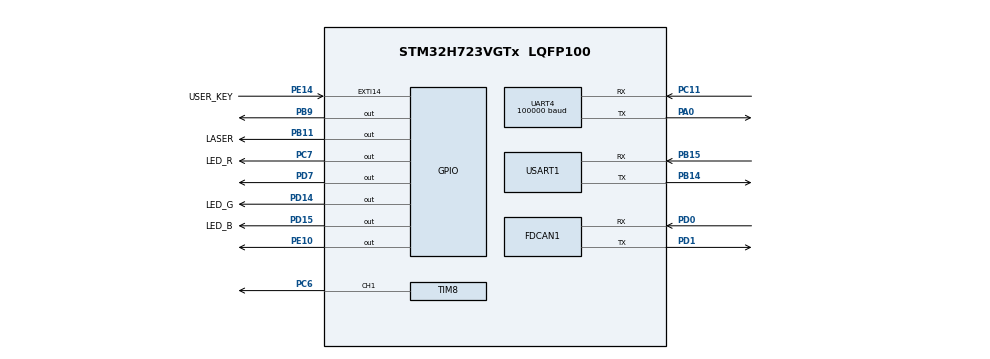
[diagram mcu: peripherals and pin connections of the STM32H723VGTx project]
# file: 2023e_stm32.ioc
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CORTEX_M7.CPU_DCache=Disabled
CORTEX_M7.CPU_ICache=Disabled
CORTEX_M7.MPU_Control=__NULL
CORTEX_M7.default_mode_Activation=0
Dma.Request0=USART1_RX
Dma.Request1=USART1_TX
Dma.Request2=UART4_RX
Dma.UART4_RX.2.Direction=DMA_PERIPH_TO_MEMORY
Dma.UART4_RX.2.EventEnable=DISABLE
Dma.UART4_RX.2.FIFOMode=DMA_FIFOMODE_DISABLE
Dma.UART4_RX.2.Instance=DMA1_Stream2
Dma.UART4_RX.2.MemDataAlignment=DMA_MDATAALIGN_BYTE
Dma.UART4_RX.2.MemInc=DMA_MINC_ENABLE
Dma.UART4_RX.2.Mode=DMA_NORMAL
Dma.UART4_RX.2.PeriphDataAlignment=DMA_PDATAALIGN_BYTE
Dma.UART4_RX.2.PeriphInc=DMA_PINC_DISABLE
Dma.UART4_RX.2.Polarity=HAL_DMAMUX_REQ_GEN_RISING
Dma.UART4_RX.2.Priority=DMA_PRIORITY_LOW
Dma.UART4_RX.2.RequestNumber=1
Dma.UART4_RX.2.SignalID=NONE
Dma.UART4_RX.2.SyncEnable=DISABLE
Dma.UART4_RX.2.SyncPolarity=HAL_DMAMUX_SYNC_NO_EVENT
Dma.UART4_RX.2.SyncRequestNumber=1
Dma.UART4_RX.2.SyncSignalID=NONE
Dma.USART1_RX.0.Direction=DMA_PERIPH_TO_MEMORY
Dma.USART1_RX.0.EventEnable=DISABLE
Dma.USART1_RX.0.FIFOMode=DMA_FIFOMODE_DISABLE
Dma.USART1_RX.0.Instance=DMA1_Stream0
Dma.USART1_RX.0.MemDataAlignment=DMA_MDATAALIGN_BYTE
Dma.USART1_RX.0.MemInc=DMA_MINC_ENABLE
Dma.USART1_RX.0.Mode=DMA_NORMAL
Dma.USART1_RX.0.PeriphDataAlignment=DMA_PDATAALIGN_BYTE
Dma.USART1_RX.0.PeriphInc=DMA_PINC_DISABLE
Dma.USART1_RX.0.Polarity=HAL_DMAMUX_REQ_GEN_RISING
Dma.USART1_RX.0.Priority=DMA_PRIORITY_LOW
Dma.USART1_RX.0.RequestNumber=1
Dma.USART1_RX.0.SignalID=NONE
Dma.USART1_RX.0.SyncEnable=DISABLE
Dma.USART1_RX.0.SyncPolarity=HAL_DMAMUX_SYNC_NO_EVENT
Dma.USART1_RX.0.SyncRequestNumber=1
Dma.USART1_RX.0.SyncSignalID=NONE
Dma.USART1_TX.1.Direction=DMA_MEMORY_TO_PERIPH
Dma.USART1_TX.1.EventEnable=DISABLE
Dma.USART1_TX.1.FIFOMode=DMA_FIFOMODE_DISABLE
Dma.USART1_TX.1.Instance=DMA1_Stream1
Dma.USART1_TX.1.MemDataAlignment=DMA_MDATAALIGN_BYTE
Dma.USART1_TX.1.MemInc=DMA_MINC_ENABLE
Dma.USART1_TX.1.Mode=DMA_NORMAL
Dma.USART1_TX.1.PeriphDataAlignment=DMA_PDATAALIGN_BYTE
Dma.USART1_TX.1.PeriphInc=DMA_PINC_DISABLE
Dma.USART1_TX.1.Polarity=HAL_DMAMUX_REQ_GEN_RISING
Dma.USART1_TX.1.Priority=DMA_PRIORITY_LOW
Dma.USART1_TX.1.RequestNumber=1
Dma.USART1_TX.1.SignalID=NONE
Dma.USART1_TX.1.SyncEnable=DISABLE
Dma.USART1_TX.1.SyncPolarity=HAL_DMAMUX_SYNC_NO_EVENT
Dma.USART1_TX.1.SyncRequestNumber=1
Dma.USART1_TX.1.SyncSignalID=NONE
FDCAN1.CalculateBaudRateNominal=999999
FDCAN1.CalculateTimeBitNominal=1000
FDCAN1.CalculateTimeQuantumNominal=9.090909090909092
FDCAN1.ClockCalibrationCCU=DISABLE
FDCAN1.NominalPrescaler=1
FDCAN1.NominalTimeSeg1=68
FDCAN1.NominalTimeSeg2=41
FDCAN1.RxFifo0ElmtsNbr=32
FDCAN1.TxFifoQueueElmtsNbr=16
Mcu.Family=STM32H7
Mcu.Name=STM32H723VGTx
Mcu.Package=LQFP100
NVIC.DMA1_Stream0_IRQn=true\:0\:0\:false\:false\:true\:false\:true\:true
NVIC.DMA1_Stream1_IRQn=true\:0\:0\:false\:false\:true\:false\:true\:true
NVIC.DMA1_Stream2_IRQn=true\:0\:0\:false\:false\:true\:false\:true\:true
NVIC.EXTI15_10_IRQn=true\:0\:0\:false\:false\:true\:true\:true\:true
NVIC.FDCAN1_IT0_IRQn=true\:5\:0\:true\:false\:true\:true\:true\:true
NVIC.FDCAN1_IT1_IRQn=true\:0\:0\:false\:false\:true\:true\:true\:true
NVIC.PriorityGroup=NVIC_PRIORITYGROUP_4
NVIC.TIM6_DAC_IRQn=true\:15\:0\:false\:false\:true\:false\:true\:true
NVIC.TimeBase=TIM6_DAC_IRQn
NVIC.TimeBaseIP=TIM6
NVIC.USART1_IRQn=true\:0\:0\:false\:false\:true\:true\:true\:true
PA0.Mode=Asynchronous
PA0.Signal=UART4_TX
PA13(JTMS/SWDIO).Mode=Serial_Wire
PA13(JTMS/SWDIO).Signal=DEBUG_JTMS-SWDIO
PA14(JTCK/SWCLK).Mode=Serial_Wire
PA14(JTCK/SWCLK).Signal=DEBUG_JTCK-SWCLK
PB11.GPIO_Label=LASER
PB11.PinState=GPIO_PIN_SET
PB11.Signal=GPIO_Output
PB14.Mode=Asynchronous
PB14.Signal=USART1_TX
PB15.Mode=Asynchronous
PB15.Signal=USART1_RX
PB9.Signal=GPIO_Output
PC11.Mode=Asynchronous
PC11.Signal=UART4_RX
PC6.Signal=S_TIM8_CH1
PC7.GPIO_Label=LED_R
PC7.PinState=GPIO_PIN_SET
PC7.Signal=GPIO_Output
PD0.Mode=FDCAN_Activate
PD0.Signal=FDCAN1_RX
PD1.Mode=FDCAN_Activate
PD1.Signal=FDCAN1_TX
PD14.GPIO_Label=LED_G
PD14.PinState=GPIO_PIN_SET
PD14.Signal=GPIO_Output
PD15.GPIO_Label=LED_B
PD15.PinState=GPIO_PIN_SET
PD15.Signal=GPIO_Output
PD7.Signal=GPIO_Output
PE10.GPIO_Speed=GPIO_SPEED_FREQ_LOW
PE10.PinState=GPIO_PIN_SET
PE10.Signal=GPIO_Output
PE14.GPIO_Label=USER_KEY
PE14.Signal=GPXTI14
PH0-OSC_IN.Mode=HSE-External-Clock-Source
PH0-OSC_IN.Signal=RCC_OSC_IN
ProjectManager.HeapSize=0x19000
ProjectManager.StackSize=0x19000
ProjectManager.TargetToolchain=CMake
RCC.ADCFreq_Value=12800000
RCC.APB1Freq_Value=137500000
RCC.APB2Freq_Value=137500000
RCC.APB3Freq_Value=137500000
RCC.APB4Freq_Value=137500000
RCC.CortexFreq_Value=550000000
RCC.D1PPRE=RCC_APB3_DIV2
RCC.D2PPRE1=RCC_APB1_DIV2
RCC.D2PPRE2=RCC_APB2_DIV2
RCC.D3PPRE=RCC_APB4_DIV2
RCC.DIVM1=1
RCC.DIVM2=1
RCC.DIVM3=1
RCC.DIVN1=68
RCC.DIVN2=24
RCC.DIVN3=24
RCC.DIVP1=1
RCC.DIVP2=15
RCC.DIVQ1=5
RCC.DIVQ3=4
RCC.HCLKFreq_Value=275000000
RCC.HPRE=RCC_HCLK_DIV2
RCC.HSE_VALUE=8000000
RCC.PLL2FRACN=0
RCC.PLL3FRACN=0
RCC.PLLFRACN=6144
RCC.PLLSourceVirtual=RCC_PLLSOURCE_HSE
RCC.SPI123CLockSelection=RCC_SPI123CLKSOURCE_PLL3
RCC.SYSCLKFreq_VALUE=550000000
RCC.SYSCLKSource=RCC_SYSCLKSOURCE_PLLCLK
RCC.USBCLockSelection=RCC_USBCLKSOURCE_PLL3
RCC.USBFreq_Value=48000000
SH.S_TIM8_CH1.0=TIM8_CH1,PWM Generation1 CH1
TIM8.AutoReloadPreload=TIM_AUTORELOAD_PRELOAD_ENABLE
TIM8.Channel-PWM\ Generation1\ CH1=TIM_CHANNEL_1
TIM8.Period=1000-1
TIM8.Prescaler=275-1
TIM8.Pulse-PWM\ Generation1\ CH1=800-1
UART4.AutoBaudRateEnableParam=UART_ADVFEATURE_AUTOBAUDRATE_DISABLE
UART4.BaudRate=100000
UART4.DMADisableonRxErrorParam=UART_ADVFEATURE_DMA_DISABLEONRXERROR
UART4.Mode=MODE_TX_RX
UART4.OverrunDisableParam=UART_ADVFEATURE_OVERRUN_DISABLE
UART4.Parity=PARITY_EVEN
UART4.StopBits=UART_STOPBITS_2
UART4.WordLength=WORDLENGTH_9B
USART1.VirtualMode-Asynchronous=VM_ASYNC
VP_MEMORYMAP_VS_MEMORYMAP.Mode=CurAppReg
VP_SYS_VS_tim6.Mode=TIM6
VP_TIM8_VS_ClockSourceINT.Mode=Internal
VP_VREFBUF_V_VREFBUF.Mode=ExternalMode
board=custom

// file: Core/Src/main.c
/* USER CODE BEGIN Header */
/**
 ******************************************************************************
 * @file           : main.c
 * @brief          : Main program body
 ******************************************************************************
 * @attention
 *
 * Copyright (c) 2025 STMicroelectronics.
 * All rights reserved.
 *
 * This software is licensed under terms that can be found in the LICENSE file
 * in the root directory of this software component.
 * If no LICENSE file comes with this software, it is provided AS-IS.
 *
 ******************************************************************************
 */
/* USER CODE END Header */
#include "main.h"
#include "dma.h"
#include "fdcan.h"
#include "memorymap.h"
#include "tim.h"
#include "usart.h"
#include "gpio.h"

void SystemClock_Config(void);
/* USER CODE BEGIN PFP */
void Init(void);
void MainLoop(void);
/* USER CODE END PFP */

int main(void)
{

  /* MCU Configuration--------------------------------------------------------*/

  /* Reset of all peripherals, Initializes the Flash interface and the Systick. */
  HAL_Init();

  /* Configure the system clock */
  SystemClock_Config();

  /* Initialize all configured peripherals */
  MX_GPIO_Init();
  MX_DMA_Init();
  MX_FDCAN1_Init();
  MX_TIM8_Init();
  MX_USART1_UART_Init();
  MX_UART4_Init();
  /* USER CODE BEGIN 2 */
  Init();
  /* USER CODE END 2 */

  /* Infinite loop */
  while (1) {

    /* USER CODE BEGIN 3 */
    MainLoop();
    HAL_Delay(1);
  }
  /* USER CODE END 3 */
}

void SystemClock_Config(void)
{
  RCC_OscInitTypeDef RCC_OscInitStruct = {0};
  RCC_ClkInitTypeDef RCC_ClkInitStruct = {0};

  /** Supply configuration update enable
  */
  HAL_PWREx_ConfigSupply(PWR_LDO_SUPPLY);

  /** Configure the main internal regulator output voltage
  */
  __HAL_PWR_VOLTAGESCALING_CONFIG(PWR_REGULATOR_VOLTAGE_SCALE0);

  while(!__HAL_PWR_GET_FLAG(PWR_FLAG_VOSRDY)) {}

  /** Initializes the RCC Oscillators according to the specified parameters
  * in the RCC_OscInitTypeDef structure.
  */
  RCC_OscInitStruct.OscillatorType = RCC_OSCILLATORTYPE_HSE;
  RCC_OscInitStruct.HSEState = RCC_HSE_BYPASS;
  RCC_OscInitStruct.PLL.PLLState = RCC_PLL_ON;
  RCC_OscInitStruct.PLL.PLLSource = RCC_PLLSOURCE_HSE;
  RCC_OscInitStruct.PLL.PLLM = 1;
  RCC_OscInitStruct.PLL.PLLN = 68;
  RCC_OscInitStruct.PLL.PLLP = 1;
  RCC_OscInitStruct.PLL.PLLQ = 5;
  RCC_OscInitStruct.PLL.PLLR = 2;
  RCC_OscInitStruct.PLL.PLLRGE = RCC_PLL1VCIRANGE_3;
  RCC_OscInitStruct.PLL.PLLVCOSEL = RCC_PLL1VCOWIDE;
  RCC_OscInitStruct.PLL.PLLFRACN = 6144;
  if (HAL_RCC_OscConfig(&RCC_OscInitStruct) != HAL_OK)
  {
    Error_Handler();
  }

  /** Initializes the CPU, AHB and APB buses clocks
  */
  RCC_ClkInitStruct.ClockType = RCC_CLOCKTYPE_HCLK|RCC_CLOCKTYPE_SYSCLK
                              |RCC_CLOCKTYPE_PCLK1|RCC_CLOCKTYPE_PCLK2
                              |RCC_CLOCKTYPE_D3PCLK1|RCC_CLOCKTYPE_D1PCLK1;
  RCC_ClkInitStruct.SYSCLKSource = RCC_SYSCLKSOURCE_PLLCLK;
  RCC_ClkInitStruct.SYSCLKDivider = RCC_SYSCLK_DIV1;
  RCC_ClkInitStruct.AHBCLKDivider = RCC_HCLK_DIV2;
  RCC_ClkInitStruct.APB3CLKDivider = RCC_APB3_DIV2;
  RCC_ClkInitStruct.APB1CLKDivider = RCC_APB1_DIV2;
  RCC_ClkInitStruct.APB2CLKDivider = RCC_APB2_DIV2;
  RCC_ClkInitStruct.APB4CLKDivider = RCC_APB4_DIV2;

  if (HAL_RCC_ClockConfig(&RCC_ClkInitStruct, FLASH_LATENCY_3) != HAL_OK)
  {
    Error_Handler();
  }
}

void HAL_TIM_PeriodElapsedCallback(TIM_HandleTypeDef *htim)
{
  if (htim->Instance == TIM6) {
    HAL_IncTick();
  }
}

void Error_Handler(void)
{
  __disable_irq();
  while (1) {
  }
}
